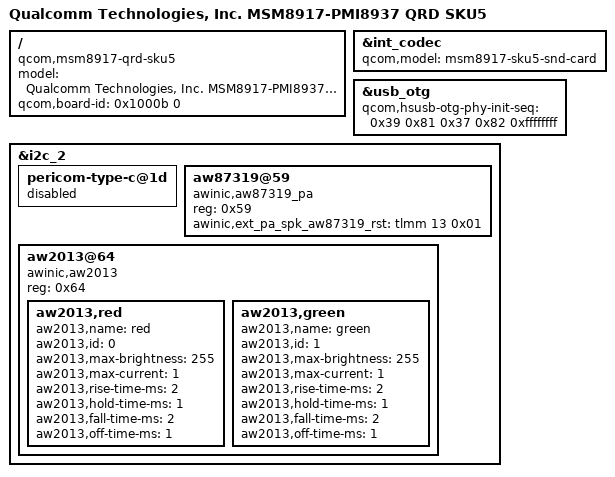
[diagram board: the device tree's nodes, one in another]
/*
 * Copyright (c) 2016, The Linux Foundation. All rights reserved.
 *
 * This program is free software; you can redistribute it and/or modify
 * it under the terms of the GNU General Public License version 2 and
 * only version 2 as published by the Free Software Foundation.
 *
 * This program is distributed in the hope that it will be useful,
 * but WITHOUT ANY WARRANTY; without even the implied warranty of
 * MERCHANTABILITY or FITNESS FOR A PARTICULAR PURPOSE.  See the
 * GNU General Public License for more details.
 */

/dts-v1/;

#include "msm8917.dtsi"
#include "msm8917-pmi8937-qrd-sku5.dtsi"

/ {
	model = "Qualcomm Technologies, Inc. MSM8917-PMI8937 QRD SKU5";
	compatible = "qcom,msm8917-qrd-sku5", "qcom,msm8917-qrd",
		   "qcom,msm8917", "qcom,qrd";
	qcom,board-id= <0x1000b 0>;
};

&int_codec {
	qcom,model = "msm8917-sku5-snd-card";
};

&usb_otg {
	qcom,hsusb-otg-phy-init-seq =
		<0x39 0x81 0x37 0x82 0xffffffff>;
};
&i2c_2 {

	pericom-type-c@1d {
		status="disabled";
	};

	/* for AW87319 sound Speaker PA */
	aw87319@59{
		compatible = "awinic,aw87319_pa";
		reg = <0x59>;
		awinic,ext_pa_spk_aw87319_rst = <&tlmm 13 0x01>;
	};

	aw2013@64 {/* add for breath led. */
		compatible = "awinic,aw2013";
		reg = <0x64>;
		//vdd-supply = <&pm8937_l17>;
		//vcc-supply = <&pm8937_l5>;

		aw2013,red {
			aw2013,name = "red";
			aw2013,id = <0>;
			aw2013,max-brightness = <255>;
			aw2013,max-current = <1>;
			aw2013,rise-time-ms = <2>;
			aw2013,hold-time-ms = <1>;
			aw2013,fall-time-ms = <2>;
			aw2013,off-time-ms = <1>;
		};

		aw2013,green {
			aw2013,name = "green";
			aw2013,id = <1>;
			aw2013,max-brightness = <255>;
			aw2013,max-current = <1>;
			aw2013,rise-time-ms = <2>;
			aw2013,hold-time-ms = <1>;
			aw2013,fall-time-ms = <2>;
			aw2013,off-time-ms = <1>;
		};
	};
};
